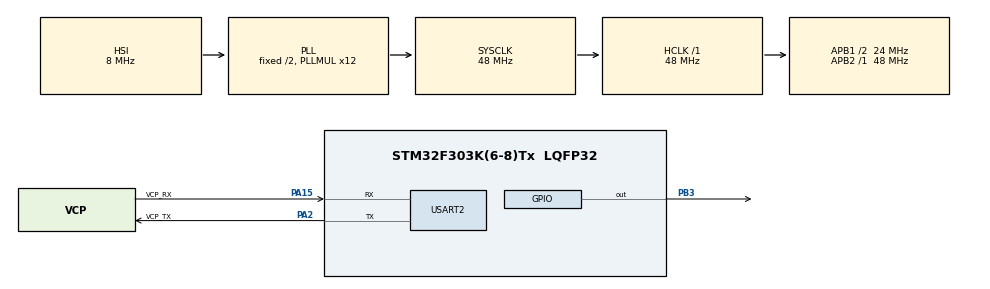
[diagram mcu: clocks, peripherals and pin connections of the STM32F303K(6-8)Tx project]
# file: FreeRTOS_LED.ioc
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FREERTOS.BinarySemaphores01=myBinarySem01,Dynamic,NULL
FREERTOS.Tasks01=defaultTask,0,128,StartDefaultTask,Default,NULL,Dynamic,NULL,NULL
Mcu.Family=STM32F3
Mcu.Name=STM32F303K(6-8)Tx
Mcu.Package=LQFP32
NVIC.PriorityGroup=NVIC_PRIORITYGROUP_4
NVIC.TIM6_DAC1_IRQn=true\:15\:0\:false\:false\:true\:false\:false\:true
NVIC.TimeBase=TIM6_DAC1_IRQn
NVIC.TimeBaseIP=TIM6
PA13.GPIO_Label=SWDIO
PA13.Mode=Serial_Wire
PA13.Signal=SYS_JTMS-SWDIO
PA14.GPIO_Label=SWCLK
PA14.Mode=Serial_Wire
PA14.Signal=SYS_JTCK-SWCLK
PA15.GPIO_Label=VCP_RX
PA15.Mode=Asynchronous
PA15.Signal=USART2_RX
PA2.GPIO_Label=VCP_TX
PA2.Mode=Asynchronous
PA2.Signal=USART2_TX
PB3.Signal=GPIO_Output
PF0\ /\ OSC_IN.GPIO_Label=MCO
PF0\ /\ OSC_IN.Mode=HSE-External-Clock-Source
PF0\ /\ OSC_IN.Signal=RCC_OSC_IN
ProjectManager.HeapSize=0x200
ProjectManager.StackSize=0x400
ProjectManager.TargetToolchain=STM32CubeIDE
RCC.AHBFreq_Value=48000000
RCC.APB1CLKDivider=RCC_HCLK_DIV2
RCC.APB1Freq_Value=24000000
RCC.APB1TimFreq_Value=48000000
RCC.APB2Freq_Value=48000000
RCC.APB2TimFreq_Value=48000000
RCC.CortexFreq_Value=48000000
RCC.HCLKFreq_Value=48000000
RCC.HSE_VALUE=8000000
RCC.HSI_VALUE=8000000
RCC.PLLMUL=RCC_PLL_MUL12
RCC.SYSCLKFreq_VALUE=48000000
RCC.SYSCLKSourceVirtual=RCC_SYSCLKSOURCE_PLLCLK
TIM1.Period=16000-1
TIM1.Prescaler=3000-1
USART2.VirtualMode-Asynchronous=VM_ASYNC
VP_FREERTOS_VS_CMSIS_V1.Mode=CMSIS_V1
VP_SYS_VS_tim6.Mode=TIM6
VP_TIM1_VS_ClockSourceINT.Mode=Internal
board=NUCLEO-F303K8

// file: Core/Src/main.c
/* USER CODE BEGIN Header */
/**
  ******************************************************************************
  * @file           : main.c
  * @brief          : Main program body
  ******************************************************************************
  * @attention
  *
  * Copyright (c) 2022 STMicroelectronics.
  * All rights reserved.
  *
  * This software is licensed under terms that can be found in the LICENSE file
  * in the root directory of this software component.
  * If no LICENSE file comes with this software, it is provided AS-IS.
  *
  ******************************************************************************
  */
/* USER CODE END Header */
#include "main.h"
#include "cmsis_os.h"

TIM_HandleTypeDef htim1;

UART_HandleTypeDef huart2;

osThreadId defaultTaskHandle;
osSemaphoreId myBinarySem01Handle;

void SystemClock_Config(void);
static void MX_GPIO_Init(void);
static void MX_USART2_UART_Init(void);
static void MX_TIM1_Init(void);
void StartDefaultTask(void const * argument);

int main(void)
{

  /* MCU Configuration--------------------------------------------------------*/

  /* Reset of all peripherals, Initializes the Flash interface and the Systick. */
  HAL_Init();

  /* Configure the system clock */
  SystemClock_Config();

  /* Initialize all configured peripherals */
  MX_GPIO_Init();
  MX_USART2_UART_Init();
  MX_TIM1_Init();

  /* Create the semaphores(s) */
  /* definition and creation of myBinarySem01 */
  osSemaphoreDef(myBinarySem01);
  myBinarySem01Handle = osSemaphoreCreate(osSemaphore(myBinarySem01), 1);

  /* USER CODE BEGIN RTOS_QUEUES */
  /* add queues, ... */
  HAL_TIM_Base_Start_IT(&htim1);
  /* USER CODE END RTOS_QUEUES */

  /* Create the thread(s) */
  /* definition and creation of defaultTask */
  osThreadDef(defaultTask, StartDefaultTask, osPriorityNormal, 0, 128);
  defaultTaskHandle = osThreadCreate(osThread(defaultTask), NULL);

  /* Start scheduler */
  osKernelStart();

  /* We should never get here as control is now taken by the scheduler */
  /* Infinite loop */
  while (1)
  {

  }
}

void SystemClock_Config(void)
{
  RCC_OscInitTypeDef RCC_OscInitStruct = {0};
  RCC_ClkInitTypeDef RCC_ClkInitStruct = {0};
  RCC_PeriphCLKInitTypeDef PeriphClkInit = {0};

  /** Initializes the RCC Oscillators according to the specified parameters
  * in the RCC_OscInitTypeDef structure.
  */
  RCC_OscInitStruct.OscillatorType = RCC_OSCILLATORTYPE_HSI;
  RCC_OscInitStruct.HSIState = RCC_HSI_ON;
  RCC_OscInitStruct.HSICalibrationValue = RCC_HSICALIBRATION_DEFAULT;
  RCC_OscInitStruct.PLL.PLLState = RCC_PLL_ON;
  RCC_OscInitStruct.PLL.PLLSource = RCC_PLLSOURCE_HSI;
  RCC_OscInitStruct.PLL.PLLMUL = RCC_PLL_MUL12;
  if (HAL_RCC_OscConfig(&RCC_OscInitStruct) != HAL_OK)
  {
    Error_Handler();
  }
  /** Initializes the CPU, AHB and APB buses clocks
  */
  RCC_ClkInitStruct.ClockType = RCC_CLOCKTYPE_HCLK|RCC_CLOCKTYPE_SYSCLK
                              |RCC_CLOCKTYPE_PCLK1|RCC_CLOCKTYPE_PCLK2;
  RCC_ClkInitStruct.SYSCLKSource = RCC_SYSCLKSOURCE_PLLCLK;
  RCC_ClkInitStruct.AHBCLKDivider = RCC_SYSCLK_DIV1;
  RCC_ClkInitStruct.APB1CLKDivider = RCC_HCLK_DIV2;
  RCC_ClkInitStruct.APB2CLKDivider = RCC_HCLK_DIV1;

  if (HAL_RCC_ClockConfig(&RCC_ClkInitStruct, FLASH_LATENCY_1) != HAL_OK)
  {
    Error_Handler();
  }
  PeriphClkInit.PeriphClockSelection = RCC_PERIPHCLK_TIM1;
  PeriphClkInit.Tim1ClockSelection = RCC_TIM1CLK_HCLK;
  if (HAL_RCCEx_PeriphCLKConfig(&PeriphClkInit) != HAL_OK)
  {
    Error_Handler();
  }
}

static void MX_TIM1_Init(void)
{

  TIM_ClockConfigTypeDef sClockSourceConfig = {0};
  TIM_MasterConfigTypeDef sMasterConfig = {0};

  htim1.Instance = TIM1;
  htim1.Init.Prescaler = 3000-1;
  htim1.Init.CounterMode = TIM_COUNTERMODE_UP;
  htim1.Init.Period = 16000-1;
  htim1.Init.ClockDivision = TIM_CLOCKDIVISION_DIV1;
  htim1.Init.RepetitionCounter = 0;
  htim1.Init.AutoReloadPreload = TIM_AUTORELOAD_PRELOAD_DISABLE;
  if (HAL_TIM_Base_Init(&htim1) != HAL_OK)
  {
    Error_Handler();
  }
  sClockSourceConfig.ClockSource = TIM_CLOCKSOURCE_INTERNAL;
  if (HAL_TIM_ConfigClockSource(&htim1, &sClockSourceConfig) != HAL_OK)
  {
    Error_Handler();
  }
  sMasterConfig.MasterOutputTrigger = TIM_TRGO_RESET;
  sMasterConfig.MasterOutputTrigger2 = TIM_TRGO2_RESET;
  sMasterConfig.MasterSlaveMode = TIM_MASTERSLAVEMODE_DISABLE;
  if (HAL_TIMEx_MasterConfigSynchronization(&htim1, &sMasterConfig) != HAL_OK)
  {
    Error_Handler();
  }

}

static void MX_USART2_UART_Init(void)
{

  huart2.Instance = USART2;
  huart2.Init.BaudRate = 38400;
  huart2.Init.WordLength = UART_WORDLENGTH_8B;
  huart2.Init.StopBits = UART_STOPBITS_1;
  huart2.Init.Parity = UART_PARITY_NONE;
  huart2.Init.Mode = UART_MODE_TX_RX;
  huart2.Init.HwFlowCtl = UART_HWCONTROL_NONE;
  huart2.Init.OverSampling = UART_OVERSAMPLING_16;
  huart2.Init.OneBitSampling = UART_ONE_BIT_SAMPLE_DISABLE;
  huart2.AdvancedInit.AdvFeatureInit = UART_ADVFEATURE_NO_INIT;
  if (HAL_UART_Init(&huart2) != HAL_OK)
  {
    Error_Handler();
  }

}

static void MX_GPIO_Init(void)
{
  GPIO_InitTypeDef GPIO_InitStruct = {0};

  /* GPIO Ports Clock Enable */
  __HAL_RCC_GPIOF_CLK_ENABLE();
  __HAL_RCC_GPIOA_CLK_ENABLE();
  __HAL_RCC_GPIOB_CLK_ENABLE();

  /*Configure GPIO pin Output Level */
  HAL_GPIO_WritePin(GPIOB, GPIO_PIN_3, GPIO_PIN_RESET);

  /*Configure GPIO pin : PB3 */
  GPIO_InitStruct.Pin = GPIO_PIN_3;
  GPIO_InitStruct.Mode = GPIO_MODE_OUTPUT_PP;
  GPIO_InitStruct.Pull = GPIO_NOPULL;
  GPIO_InitStruct.Speed = GPIO_SPEED_FREQ_LOW;
  HAL_GPIO_Init(GPIOB, &GPIO_InitStruct);

}

void StartDefaultTask(void const * argument)
{
  /* USER CODE BEGIN 5 */
  /* Infinite loop */
  for(;;)
  {
	  osSemaphoreWait(myBinarySem01Handle, osWaitForever);
	  HAL_GPIO_TogglePin(GPIOB, GPIO_PIN_3);
  }
  /* USER CODE END 5 */
}

void HAL_TIM_PeriodElapsedCallback(TIM_HandleTypeDef *htim)
{
  if (htim->Instance == TIM6) {
    HAL_IncTick();
  }
  /* USER CODE BEGIN Callback 1 */
  if (htim == &htim1)
    {
      osSemaphoreRelease(myBinarySem01Handle);
    }
  /* USER CODE END Callback 1 */
}

void Error_Handler(void)
{
  __disable_irq();
  while (1)
  {
  }
}
